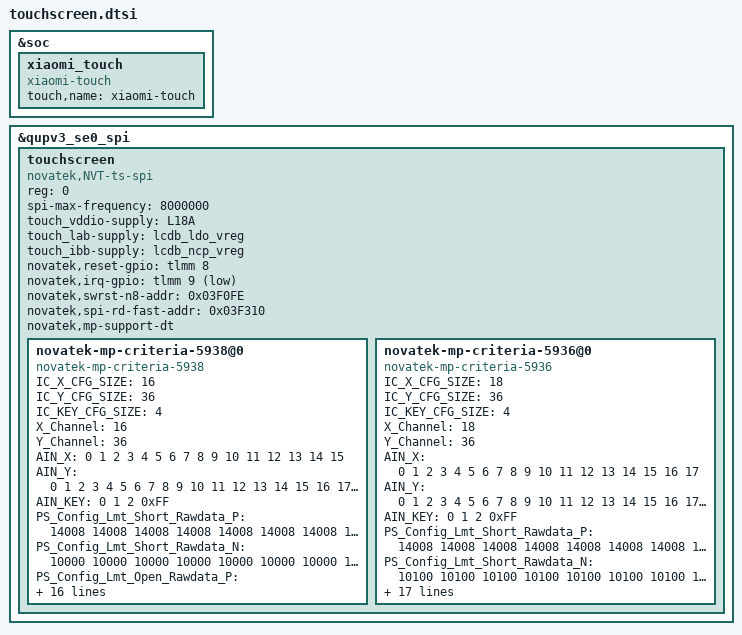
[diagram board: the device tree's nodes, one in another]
/*
 * TouchScreen Device Tree For Xiaomi J20
 */

&soc {
	xiaomi_touch {
		status = "ok";
		compatible = "xiaomi-touch";
		touch,name = "xiaomi-touch";
	};
};

&qupv3_se0_spi {
	status = "ok";

	touchscreen {
		status = "ok";
		compatible = "novatek,NVT-ts-spi";
		reg = <0 >;	//Same as CS ID

		/* SPI Configuration */
		spi-max-frequency = <8000000 >;	//4800000,5000000,8000000,9600000,15000000,19200000

		/* regulator Configuration */
		touch_vddio-supply = <&L18A>;
		touch_lab-supply = <&lcdb_ldo_vreg>;
		touch_ibb-supply = <&lcdb_ncp_vreg>;

		/*Novatek GPIO Configuration */
		novatek,reset-gpio = <&tlmm 8 0x00>;
		novatek,irq-gpio = <&tlmm 9 0x2001>;

		/* 525 */
		//novatek,swrst-n8-addr = <0x01F01A>;

		/* 672A, 525B, 675, 526 */
		novatek,swrst-n8-addr = <0x03F0FE>;
		novatek,spi-rd-fast-addr = <0x03F310>;

		/* MP */
		novatek,mp-support-dt;

		/*for Xiaomi J20 672C TM6.67" module*/
		novatek-mp-criteria-5938@0 {
			#address-cells = <1>;
			#size-cells = <0>;
			compatible = "novatek-mp-criteria-5938";

			/* MP Config */
			IC_X_CFG_SIZE = <16>;
			IC_Y_CFG_SIZE = <36>;
			IC_KEY_CFG_SIZE = <4>;
			X_Channel = <16>;
			Y_Channel = <36>;
			AIN_X = <0 1 2 3 4 5 6 7 8 9 10 11 12 13 14 15>;
			AIN_Y = <0 1 2 3 4 5 6 7 8 9 10 11 12 13 14 15 16 17
						18 19 20 21 22 23 24 25 26 27 28 29 30 31 32 33 34 35>;
			AIN_KEY = <0 1 2 0xFF>;

			/* MP Criteria */
			PS_Config_Lmt_Short_Rawdata_P = <
				14008 14008 14008 14008 14008 14008 14008 14008 14008 14008 14008 14008 14008 14008 14008 14008
				14008 14008 14008 14008 14008 14008 14008 14008 14008 14008 14008 14008 14008 14008 14008 14008
				14008 14008 14008 14008 14008 14008 14008 14008 14008 14008 14008 14008 14008 14008 14008 14008
				14008 14008 14008 14008 14008 14008 14008 14008 14008 14008 14008 14008 14008 14008 14008 14008
				14008 14008 14008 14008 14008 14008 14008 14008 14008 14008 14008 14008 14008 14008 14008 14008
				14008 14008 14008 14008 14008 14008 14008 14008 14008 14008 14008 14008 14008 14008 14008 14008
				14008 14008 14008 14008 14008 14008 14008 14008 14008 14008 14008 14008 14008 14008 14008 14008
				14008 14008 14008 14008 14008 14008 14008 14008 14008 14008 14008 14008 14008 14008 14008 14008
				14008 14008 14008 14008 14008 14008 14008 14008 14008 14008 14008 14008 14008 14008 14008 14008
				14008 14008 14008 14008 14008 14008 14008 14008 14008 14008 14008 14008 14008 14008 14008 14008
				14008 14008 14008 14008 14008 14008 14008 14008 14008 14008 14008 14008 14008 14008 14008 14008
				14008 14008 14008 14008 14008 14008 14008 14008 14008 14008 14008 14008 14008 14008 14008 14008
				14008 14008 14008 14008 14008 14008 14008 14008 14008 14008 14008 14008 14008 14008 14008 14008
				14008 14008 14008 14008 14008 14008 14008 14008 14008 14008 14008 14008 14008 14008 14008 14008
				14008 14008 14008 14008 14008 14008 14008 14008 14008 14008 14008 14008 14008 14008 14008 14008
				14008 14008 14008 14008 14008 14008 14008 14008 14008 14008 14008 14008 14008 14008 14008 14008
				14008 14008 14008 14008 14008 14008 14008 14008 14008 14008 14008 14008 14008 14008 14008 14008
				14008 14008 14008 14008 14008 14008 14008 14008 14008 14008 14008 14008 14008 14008 14008 14008
				14008 14008 14008 14008 14008 14008 14008 14008 14008 14008 14008 14008 14008 14008 14008 14008
				14008 14008 14008 14008 14008 14008 14008 14008 14008 14008 14008 14008 14008 14008 14008 14008
				14008 14008 14008 14008 14008 14008 14008 14008 14008 14008 14008 14008 14008 14008 14008 14008
				14008 14008 14008 14008 14008 14008 14008 14008 14008 14008 14008 14008 14008 14008 14008 14008
				14008 14008 14008 14008 14008 14008 14008 14008 14008 14008 14008 14008 14008 14008 14008 14008
				14008 14008 14008 14008 14008 14008 14008 14008 14008 14008 14008 14008 14008 14008 14008 14008
				14008 14008 14008 14008 14008 14008 14008 14008 14008 14008 14008 14008 14008 14008 14008 14008
				14008 14008 14008 14008 14008 14008 14008 14008 14008 14008 14008 14008 14008 14008 14008 14008
				14008 14008 14008 14008 14008 14008 14008 14008 14008 14008 14008 14008 14008 14008 14008 14008
				14008 14008 14008 14008 14008 14008 14008 14008 14008 14008 14008 14008 14008 14008 14008 14008
				14008 14008 14008 14008 14008 14008 14008 14008 14008 14008 14008 14008 14008 14008 14008 14008
				14008 14008 14008 14008 14008 14008 14008 14008 14008 14008 14008 14008 14008 14008 14008 14008
				14008 14008 14008 14008 14008 14008 14008 14008 14008 14008 14008 14008 14008 14008 14008 14008
				14008 14008 14008 14008 14008 14008 14008 14008 14008 14008 14008 14008 14008 14008 14008 14008
				14008 14008 14008 14008 14008 14008 14008 14008 14008 14008 14008 14008 14008 14008 14008 14008
				14008 14008 14008 14008 14008 14008 14008 14008 14008 14008 14008 14008 14008 14008 14008 14008
				14008 14008 14008 14008 14008 14008 14008 14008 14008 14008 14008 14008 14008 14008 14008 14008
				14008 14008 14008 14008 14008 14008 14008 14008 14008 14008 14008 14008 14008 14008 14008 14008
				14008 14008 14008>;

			PS_Config_Lmt_Short_Rawdata_N = <
				10000 10000 10000 10000 10000 10000 10000 10000 10000 10000 10000 10000 10000 10000 10000 10000
				10000 10000 10000 10000 10000 10000 10000 10000 10000 10000 10000 10000 10000 10000 10000 10000
				10000 10000 10000 10000 10000 10000 10000 10000 10000 10000 10000 10000 10000 10000 10000 10000
				10000 10000 10000 10000 10000 10000 10000 10000 10000 10000 10000 10000 10000 10000 10000 10000
				10000 10000 10000 10000 10000 10000 10000 10000 10000 10000 10000 10000 10000 10000 10000 10000
				10000 10000 10000 10000 10000 10000 10000 10000 10000 10000 10000 10000 10000 10000 10000 10000
				10000 10000 10000 10000 10000 10000 10000 10000 10000 10000 10000 10000 10000 10000 10000 10000
				10000 10000 10000 10000 10000 10000 10000 10000 10000 10000 10000 10000 10000 10000 10000 10000
				10000 10000 10000 10000 10000 10000 10000 10000 10000 10000 10000 10000 10000 10000 10000 10000
				10000 10000 10000 10000 10000 10000 10000 10000 10000 10000 10000 10000 10000 10000 10000 10000
				10000 10000 10000 10000 10000 10000 10000 10000 10000 10000 10000 10000 10000 10000 10000 10000
				10000 10000 10000 10000 10000 10000 10000 10000 10000 10000 10000 10000 10000 10000 10000 10000
				10000 10000 10000 10000 10000 10000 10000 10000 10000 10000 10000 10000 10000 10000 10000 10000
				10000 10000 10000 10000 10000 10000 10000 10000 10000 10000 10000 10000 10000 10000 10000 10000
				10000 10000 10000 10000 10000 10000 10000 10000 10000 10000 10000 10000 10000 10000 10000 10000
				10000 10000 10000 10000 10000 10000 10000 10000 10000 10000 10000 10000 10000 10000 10000 10000
				10000 10000 10000 10000 10000 10000 10000 10000 10000 10000 10000 10000 10000 10000 10000 10000
				10000 10000 10000 10000 10000 10000 10000 10000 10000 10000 10000 10000 10000 10000 10000 10000
				10000 10000 10000 10000 10000 10000 10000 10000 10000 10000 10000 10000 10000 10000 10000 10000
				10000 10000 10000 10000 10000 10000 10000 10000 10000 10000 10000 10000 10000 10000 10000 10000
				10000 10000 10000 10000 10000 10000 10000 10000 10000 10000 10000 10000 10000 10000 10000 10000
				10000 10000 10000 10000 10000 10000 10000 10000 10000 10000 10000 10000 10000 10000 10000 10000
				10000 10000 10000 10000 10000 10000 10000 10000 10000 10000 10000 10000 10000 10000 10000 10000
				10000 10000 10000 10000 10000 10000 10000 10000 10000 10000 10000 10000 10000 10000 10000 10000
				10000 10000 10000 10000 10000 10000 10000 10000 10000 10000 10000 10000 10000 10000 10000 10000
				10000 10000 10000 10000 10000 10000 10000 10000 10000 10000 10000 10000 10000 10000 10000 10000
				10000 10000 10000 10000 10000 10000 10000 10000 10000 10000 10000 10000 10000 10000 10000 10000
				10000 10000 10000 10000 10000 10000 10000 10000 10000 10000 10000 10000 10000 10000 10000 10000
				10000 10000 10000 10000 10000 10000 10000 10000 10000 10000 10000 10000 10000 10000 10000 10000
				10000 10000 10000 10000 10000 10000 10000 10000 10000 10000 10000 10000 10000 10000 10000 10000
				10000 10000 10000 10000 10000 10000 10000 10000 10000 10000 10000 10000 10000 10000 10000 10000
				10000 10000 10000 10000 10000 10000 10000 10000 10000 10000 10000 10000 10000 10000 10000 10000
				10000 10000 10000 10000 10000 10000 10000 10000 10000 10000 10000 10000 10000 10000 10000 10000
				10000 10000 10000 10000 10000 10000 10000 10000 10000 10000 10000 10000 10000 10000 10000 10000
				10000 10000 10000 10000 10000 10000 10000 10000 10000 10000 10000 10000 10000 10000 10000 10000
				10000 10000 10000 10000 10000 10000 10000 10000 10000 10000 10000 10000 10000 10000 10000 10000
				10000 10000 10000>;

			PS_Config_Lmt_Open_Rawdata_P = <
				5120 5120 5120 5120 5120 5120 5120 5120 5120 5120 5120 5120 5120 5120 5120 5120
				5120 5120 5120 5120 5120 5120 5120 5120 5120 5120 5120 5120 5120 5120 5120 5120
				5120 5120 5120 5120 5120 5120 5120 5120 5120 5120 5120 5120 5120 5120 5120 5120
				5120 5120 5120 5120 5120 5120 5120 5120 5120 5120 5120 5120 5120 5120 5120 5120
				5120 5120 5120 5120 5120 5120 5120 5120 5120 5120 5120 5120 5120 5120 5120 5120
				5120 5120 5120 5120 5120 5120 5120 5120 5120 5120 5120 5120 5120 5120 5120 5120
				5120 5120 5120 5120 5120 5120 5120 5120 5120 5120 5120 5120 5120 5120 5120 5120
				5120 5120 5120 5120 5120 5120 5120 5120 5120 5120 5120 5120 5120 5120 5120 5120
				5120 5120 5120 5120 5120 5120 5120 5120 5120 5120 5120 5120 5120 5120 5120 5120
				5120 5120 5120 5120 5120 5120 5120 5120 5120 5120 5120 5120 5120 5120 5120 5120
				5120 5120 5120 5120 5120 5120 5120 5120 5120 5120 5120 5120 5120 5120 5120 5120
				5120 5120 5120 5120 5120 5120 5120 5120 5120 5120 5120 5120 5120 5120 5120 5120
				5120 5120 5120 5120 5120 5120 5120 5120 5120 5120 5120 5120 5120 5120 5120 5120
				5120 5120 5120 5120 5120 5120 5120 5120 5120 5120 5120 5120 5120 5120 5120 5120
				5120 5120 5120 5120 5120 5120 5120 5120 5120 5120 5120 5120 5120 5120 5120 5120
				5120 5120 5120 5120 5120 5120 5120 5120 5120 5120 5120 5120 5120 5120 5120 5120
				5120 5120 5120 5120 5120 5120 5120 5120 5120 5120 5120 5120 5120 5120 5120 5120
				5120 5120 5120 5120 5120 5120 5120 5120 5120 5120 5120 5120 5120 5120 5120 5120
				5120 5120 5120 5120 5120 5120 5120 5120 5120 5120 5120 5120 5120 5120 5120 5120
				5120 5120 5120 5120 5120 5120 5120 5120 5120 5120 5120 5120 5120 5120 5120 5120
				5120 5120 5120 5120 5120 5120 5120 5120 5120 5120 5120 5120 5120 5120 5120 5120
				5120 5120 5120 5120 5120 5120 5120 5120 5120 5120 5120 5120 5120 5120 5120 5120
				5120 5120 5120 5120 5120 5120 5120 5120 5120 5120 5120 5120 5120 5120 5120 5120
				5120 5120 5120 5120 5120 5120 5120 5120 5120 5120 5120 5120 5120 5120 5120 5120
				5120 5120 5120 5120 5120 5120 5120 5120 5120 5120 5120 5120 5120 5120 5120 5120
				5120 5120 5120 5120 5120 5120 5120 5120 5120 5120 5120 5120 5120 5120 5120 5120
				5120 5120 5120 5120 5120 5120 5120 5120 5120 5120 5120 5120 5120 5120 5120 5120
				5120 5120 5120 5120 5120 5120 5120 5120 5120 5120 5120 5120 5120 5120 5120 5120
				5120 5120 5120 5120 5120 5120 5120 5120 5120 5120 5120 5120 5120 5120 5120 5120
				5120 5120 5120 5120 5120 5120 5120 5120 5120 5120 5120 5120 5120 5120 5120 5120
				5120 5120 5120 5120 5120 5120 5120 5120 5120 5120 5120 5120 5120 5120 5120 5120
				5120 5120 5120 5120 5120 5120 5120 5120 5120 5120 5120 5120 5120 5120 5120 5120
				5120 5120 5120 5120 5120 5120 5120 5120 5120 5120 5120 5120 5120 5120 5120 5120
				5120 5120 5120 5120 5120 5120 5120 5120 5120 5120 5120 5120 5120 5120 5120 5120
				5120 5120 5120 5120 5120 5120 5120 5120 5120 5120 5120 5120 5120 5120 5120 5120
				5120 5120 5120 5120 5120 5120 5120 5120 5120 5120 5120 5120 5120 5120 5120 5120
				5120 5120 5120>;

			PS_Config_Lmt_Open_Rawdata_N = <
		(-511) (-511) (-511) (-511) (-511) (-511) (-511) (-511) (-511) (-511) (-511) (-511) (-511) (-511) (-511) (-511)
		(-511) (-511) (-511) (-511) (-511) (-511) (-511) (-511) (-511) (-511) (-511) (-511) (-511) (-511) (-511) (-511)
		(-511) (-511) (-511) (-511) (-511) (-511) (-511) (-511) (-511) (-511) (-511) (-511) (-511) (-511) (-511) (-511)
		(-511) (-511) (-511) (-511) (-511) (-511) (-511) (-511) (-511) (-511) (-511) (-511) (-511) (-511) (-511) (-511)
		(-511) (-511) (-511) (-511) (-511) (-511) (-511) (-511) (-511) (-511) (-511) (-511) (-511) (-511) (-511) (-511)
		(-511) (-511) (-511) (-511) (-511) (-511) (-511) (-511) (-511) (-511) (-511) (-511) (-511) (-511) (-511) (-511)
		(-511) (-511) (-511) (-511) (-511) (-511) (-511) (-511) (-511) (-511) (-511) (-511) (-511) (-511) (-511) (-511)
		(-511) (-511) (-511) (-511) (-511) (-511) (-511) (-511) (-511) (-511) (-511) (-511) (-511) (-511) (-511) (-511)
		(-511) (-511) (-511) (-511) (-511) (-511) (-511) (-511) (-511) (-511) (-511) (-511) (-511) (-511) (-511) (-511)
		(-511) (-511) (-511) (-511) (-511) (-511) (-511) (-511) (-511) (-511) (-511) (-511) (-511) (-511) (-511) (-511)
		(-511) (-511) (-511) (-511) (-511) (-511) (-511) (-511) (-511) (-511) (-511) (-511) (-511) (-511) (-511) (-511)
		(-511) (-511) (-511) (-511) (-511) (-511) (-511) (-511) (-511) (-511) (-511) (-511) (-511) (-511) (-511) (-511)
		(-511) (-511) (-511) (-511) (-511) (-511) (-511) (-511) (-511) (-511) (-511) (-511) (-511) (-511) (-511) (-511)
		(-511) (-511) (-511) (-511) (-511) (-511) (-511) (-511) (-511) (-511) (-511) (-511) (-511) (-511) (-511) (-511)
		(-511) (-511) (-511) (-511) (-511) (-511) (-511) (-511) (-511) (-511) (-511) (-511) (-511) (-511) (-511) (-511)
		(-511) (-511) (-511) (-511) (-511) (-511) (-511) (-511) (-511) (-511) (-511) (-511) (-511) (-511) (-511) (-511)
		(-511) (-511) (-511) (-511) (-511) (-511) (-511) (-511) (-511) (-511) (-511) (-511) (-511) (-511) (-511) (-511)
		(-511) (-511) (-511) (-511) (-511) (-511) (-511) (-511) (-511) (-511) (-511) (-511) (-511) (-511) (-511) (-511)
		(-511) (-511) (-511) (-511) (-511) (-511) (-511) (-511) (-511) (-511) (-511) (-511) (-511) (-511) (-511) (-511)
		(-511) (-511) (-511) (-511) (-511) (-511) (-511) (-511) (-511) (-511) (-511) (-511) (-511) (-511) (-511) (-511)
		(-511) (-511) (-511) (-511) (-511) (-511) (-511) (-511) (-511) (-511) (-511) (-511) (-511) (-511) (-511) (-511)
		(-511) (-511) (-511) (-511) (-511) (-511) (-511) (-511) (-511) (-511) (-511) (-511) (-511) (-511) (-511) (-511)
		(-511) (-511) (-511) (-511) (-511) (-511) (-511) (-511) (-511) (-511) (-511) (-511) (-511) (-511) (-511) (-511)
		(-511) (-511) (-511) (-511) (-511) (-511) (-511) (-511) (-511) (-511) (-511) (-511) (-511) (-511) (-511) (-511)
		(-511) (-511) (-511) (-511) (-511) (-511) (-511) (-511) (-511) (-511) (-511) (-511) (-511) (-511) (-511) (-511)
		(-511) (-511) (-511) (-511) (-511) (-511) (-511) (-511) (-511) (-511) (-511) (-511) (-511) (-511) (-511) (-511)
		(-511) (-511) (-511) (-511) (-511) (-511) (-511) (-511) (-511) (-511) (-511) (-511) (-511) (-511) (-511) (-511)
		(-511) (-511) (-511) (-511) (-511) (-511) (-511) (-511) (-511) (-511) (-511) (-511) (-511) (-511) (-511) (-511)
		(-511) (-511) (-511) (-511) (-511) (-511) (-511) (-511) (-511) (-511) (-511) (-511) (-511) (-511) (-511) (-511)
		(-511) (-511) (-511) (-511) (-511) (-511) (-511) (-511) (-511) (-511) (-511) (-511) (-511) (-511) (-511) (-511)
		(-511) (-511) (-511) (-511) (-511) (-511) (-511) (-511) (-511) (-511) (-511) (-511) (-511) (-511) (-511) (-511)
		(-511) (-511) (-511) (-511) (-511) (-511) (-511) (-511) (-511) (-511) (-511) (-511) (-511) (-511) (-511) (-511)
		(-511) (-511) (-511) (-511) (-511) (-511) (-511) (-511) (-511) (-511) (-511) (-511) (-511) (-511) (-511) (-511)
		(-511) (-511) (-511) (-511) (-511) (-511) (-511) (-511) (-511) (-511) (-511) (-511) (-511) (-511) (-511) (-511)
		(-511) (-511) (-511) (-511) (-511) (-511) (-511) (-511) (-511) (-511) (-511) (-511) (-511) (-511) (-511) (-511)
		(-511) (-511) (-511) (-511) (-511) (-511) (-511) (-511) (-511) (-511) (-511) (-511) (-511) (-511) (-511) (-511)
		(-511) (-511) (-511)>;

			PS_Config_Lmt_FW_Rawdata_P = <
				2560 2560 2560 2560 2560 2560 2560 2560 2560 2560 2560 2560 2560 2560 2560 2560
				2560 2560 2560 2560 2560 2560 2560 2560 2560 2560 2560 2560 2560 2560 2560 2560
				2560 2560 2560 2560 2560 2560 2560 2560 2560 2560 2560 2560 2560 2560 2560 2560
				2560 2560 2560 2560 2560 2560 2560 2560 2560 2560 2560 2560 2560 2560 2560 2560
				2560 2560 2560 2560 2560 2560 2560 2560 2560 2560 2560 2560 2560 2560 2560 2560
				2560 2560 2560 2560 2560 2560 2560 2560 2560 2560 2560 2560 2560 2560 2560 2560
				2560 2560 2560 2560 2560 2560 2560 2560 2560 2560 2560 2560 2560 2560 2560 2560
				2560 2560 2560 2560 2560 2560 2560 2560 2560 2560 2560 2560 2560 2560 2560 2560
				2560 2560 2560 2560 2560 2560 2560 2560 2560 2560 2560 2560 2560 2560 2560 2560
				2560 2560 2560 2560 2560 2560 2560 2560 2560 2560 2560 2560 2560 2560 2560 2560
				2560 2560 2560 2560 2560 2560 2560 2560 2560 2560 2560 2560 2560 2560 2560 2560
				2560 2560 2560 2560 2560 2560 2560 2560 2560 2560 2560 2560 2560 2560 2560 2560
				2560 2560 2560 2560 2560 2560 2560 2560 2560 2560 2560 2560 2560 2560 2560 2560
				2560 2560 2560 2560 2560 2560 2560 2560 2560 2560 2560 2560 2560 2560 2560 2560
				2560 2560 2560 2560 2560 2560 2560 2560 2560 2560 2560 2560 2560 2560 2560 2560
				2560 2560 2560 2560 2560 2560 2560 2560 2560 2560 2560 2560 2560 2560 2560 2560
				2560 2560 2560 2560 2560 2560 2560 2560 2560 2560 2560 2560 2560 2560 2560 2560
				2560 2560 2560 2560 2560 2560 2560 2560 2560 2560 2560 2560 2560 2560 2560 2560
				2560 2560 2560 2560 2560 2560 2560 2560 2560 2560 2560 2560 2560 2560 2560 2560
				2560 2560 2560 2560 2560 2560 2560 2560 2560 2560 2560 2560 2560 2560 2560 2560
				2560 2560 2560 2560 2560 2560 2560 2560 2560 2560 2560 2560 2560 2560 2560 2560
				2560 2560 2560 2560 2560 2560 2560 2560 2560 2560 2560 2560 2560 2560 2560 2560
				2560 2560 2560 2560 2560 2560 2560 2560 2560 2560 2560 2560 2560 2560 2560 2560
				2560 2560 2560 2560 2560 2560 2560 2560 2560 2560 2560 2560 2560 2560 2560 2560
				2560 2560 2560 2560 2560 2560 2560 2560 2560 2560 2560 2560 2560 2560 2560 2560
				2560 2560 2560 2560 2560 2560 2560 2560 2560 2560 2560 2560 2560 2560 2560 2560
				2560 2560 2560 2560 2560 2560 2560 2560 2560 2560 2560 2560 2560 2560 2560 2560
				2560 2560 2560 2560 2560 2560 2560 2560 2560 2560 2560 2560 2560 2560 2560 2560
				2560 2560 2560 2560 2560 2560 2560 2560 2560 2560 2560 2560 2560 2560 2560 2560
				2560 2560 2560 2560 2560 2560 2560 2560 2560 2560 2560 2560 2560 2560 2560 2560
				2560 2560 2560 2560 2560 2560 2560 2560 2560 2560 2560 2560 2560 2560 2560 2560
				2560 2560 2560 2560 2560 2560 2560 2560 2560 2560 2560 2560 2560 2560 2560 2560
				2560 2560 2560 2560 2560 2560 2560 2560 2560 2560 2560 2560 2560 2560 2560 2560
				2560 2560 2560 2560 2560 2560 2560 2560 2560 2560 2560 2560 2560 2560 2560 2560
				2560 2560 2560 2560 2560 2560 2560 2560 2560 2560 2560 2560 2560 2560 2560 2560
				2560 2560 2560 2560 2560 2560 2560 2560 2560 2560 2560 2560 2560 2560 2560 2560
				2560 2560 2560>;

			PS_Config_Lmt_FW_Rawdata_N = <
				240 240 240 240 240 240 240 240 240 240 240 240 240 240 240 240
				240 240 240 240 240 240 240 240 240 240 240 240 240 240 240 240
				240 240 240 240 240 240 240 240 240 240 240 240 240 240 240 240
				240 240 240 240 240 240 240 240 240 240 240 240 240 240 240 240
				240 240 240 240 240 240 240 240 240 240 240 240 240 240 240 240
				240 240 240 240 240 240 240 240 240 240 240 240 240 240 240 240
				240 240 240 240 240 240 240 240 240 240 240 240 240 240 240 240
				240 240 240 240 240 240 240 240 240 240 240 240 240 240 240 240
				240 240 240 240 240 240 240 240 240 240 240 240 240 240 240 240
				240 240 240 240 240 240 240 240 240 240 240 240 240 240 240 240
				240 240 240 240 240 240 240 240 240 240 240 240 240 240 240 240
				240 240 240 240 240 240 240 240 240 240 240 240 240 240 240 240
				240 240 240 240 240 240 240 240 240 240 240 240 240 240 240 240
				240 240 240 240 240 240 240 240 240 240 240 240 240 240 240 240
				240 240 240 240 240 240 240 240 240 240 240 240 240 240 240 240
				240 240 240 240 240 240 240 240 240 240 240 240 240 240 240 240
				240 240 240 240 240 240 240 240 240 240 240 240 240 240 240 240
				240 240 240 240 240 240 240 240 240 240 240 240 240 240 240 240
				240 240 240 240 240 240 240 240 240 240 240 240 240 240 240 240
				240 240 240 240 240 240 240 240 240 240 240 240 240 240 240 240
				240 240 240 240 240 240 240 240 240 240 240 240 240 240 240 240
				240 240 240 240 240 240 240 240 240 240 240 240 240 240 240 240
				240 240 240 240 240 240 240 240 240 240 240 240 240 240 240 240
				240 240 240 240 240 240 240 240 240 240 240 240 240 240 240 240
				240 240 240 240 240 240 240 240 240 240 240 240 240 240 240 240
				240 240 240 240 240 240 240 240 240 240 240 240 240 240 240 240
				240 240 240 240 240 240 240 240 240 240 240 240 240 240 240 240
				240 240 240 240 240 240 240 240 240 240 240 240 240 240 240 240
				240 240 240 240 240 240 240 240 240 240 240 240 240 240 240 240
				240 240 240 240 240 240 240 240 240 240 240 240 240 240 240 240
				240 240 240 240 240 240 240 240 240 240 240 240 240 240 240 240
				240 240 240 240 240 240 240 240 240 240 240 240 240 240 240 240
				240 240 240 240 240 240 240 240 240 240 240 240 240 240 240 240
				240 240 240 240 240 240 240 240 240 240 240 240 240 240 240 240
				240 240 240 240 240 240 240 240 240 240 240 240 240 240 240 240
				240 240 240 240 240 240 240 240 240 240 240 240 240 240 240 240
				240 240 240>;

			PS_Config_Lmt_FW_CC_P = <
				314 314 314 314 314 314 314 314 314 314 314 314 314 314 314 314
				314 314 314 314 314 314 314 314 314 314 314 314 314 314 314 314
				314 314 314 314 314 314 314 314 314 314 314 314 314 314 314 314
				314 314 314 314 314 314 314 314 314 314 314 314 314 314 314 314
				314 314 314 314 314 314 314 314 314 314 314 314 314 314 314 314
				314 314 314 314 314 314 314 314 314 314 314 314 314 314 314 314
				314 314 314 314 314 314 314 314 314 314 314 314 314 314 314 314
				314 314 314 314 314 314 314 314 314 314 314 314 314 314 314 314
				314 314 314 314 314 314 314 314 314 314 314 314 314 314 314 314
				314 314 314 314 314 314 314 314 314 314 314 314 314 314 314 314
				314 314 314 314 314 314 314 314 314 314 314 314 314 314 314 314
				314 314 314 314 314 314 314 314 314 314 314 314 314 314 314 314
				314 314 314 314 314 314 314 314 314 314 314 314 314 314 314 314
				314 314 314 314 314 314 314 314 314 314 314 314 314 314 314 314
				314 314 314 314 314 314 314 314 314 314 314 314 314 314 314 314
				314 314 314 314 314 314 314 314 314 314 314 314 314 314 314 314
				314 314 314 314 314 314 314 314 314 314 314 314 314 314 314 314
				314 314 314 314 314 314 314 314 314 314 314 314 314 314 314 314
				314 314 314 314 314 314 314 314 314 314 314 314 314 314 314 314
				314 314 314 314 314 314 314 314 314 314 314 314 314 314 314 314
				314 314 314 314 314 314 314 314 314 314 314 314 314 314 314 314
				314 314 314 314 314 314 314 314 314 314 314 314 314 314 314 314
				314 314 314 314 314 314 314 314 314 314 314 314 314 314 314 314
				314 314 314 314 314 314 314 314 314 314 314 314 314 314 314 314
				314 314 314 314 314 314 314 314 314 314 314 314 314 314 314 314
				314 314 314 314 314 314 314 314 314 314 314 314 314 314 314 314
				314 314 314 314 314 314 314 314 314 314 314 314 314 314 314 314
				314 314 314 314 314 314 314 314 314 314 314 314 314 314 314 314
				314 314 314 314 314 314 314 314 314 314 314 314 314 314 314 314
				314 314 314 314 314 314 314 314 314 314 314 314 314 314 314 314
				314 314 314 314 314 314 314 314 314 314 314 314 314 314 314 314
				314 314 314 314 314 314 314 314 314 314 314 314 314 314 314 314
				314 314 314 314 314 314 314 314 314 314 314 314 314 314 314 314
				314 314 314 314 314 314 314 314 314 314 314 314 314 314 314 314
				314 314 314 314 314 314 314 314 314 314 314 314 314 314 314 314
				314 314 314 314 314 314 314 314 314 314 314 314 314 314 314 314
				314 314 314>;

			PS_Config_Lmt_FW_CC_N = <
				0 0 0 0 0 0 0 0 0 0 0 0 0 0 0 0
				0 0 0 0 0 0 0 0 0 0 0 0 0 0 0 0
				0 0 0 0 0 0 0 0 0 0 0 0 0 0 0 0
				0 0 0 0 0 0 0 0 0 0 0 0 0 0 0 0
				0 0 0 0 0 0 0 0 0 0 0 0 0 0 0 0
				0 0 0 0 0 0 0 0 0 0 0 0 0 0 0 0
				0 0 0 0 0 0 0 0 0 0 0 0 0 0 0 0
				0 0 0 0 0 0 0 0 0 0 0 0 0 0 0 0
				0 0 0 0 0 0 0 0 0 0 0 0 0 0 0 0
				0 0 0 0 0 0 0 0 0 0 0 0 0 0 0 0
				0 0 0 0 0 0 0 0 0 0 0 0 0 0 0 0
				0 0 0 0 0 0 0 0 0 0 0 0 0 0 0 0
				0 0 0 0 0 0 0 0 0 0 0 0 0 0 0 0
				0 0 0 0 0 0 0 0 0 0 0 0 0 0 0 0
				0 0 0 0 0 0 0 0 0 0 0 0 0 0 0 0
				0 0 0 0 0 0 0 0 0 0 0 0 0 0 0 0
				0 0 0 0 0 0 0 0 0 0 0 0 0 0 0 0
				0 0 0 0 0 0 0 0 0 0 0 0 0 0 0 0
				0 0 0 0 0 0 0 0 0 0 0 0 0 0 0 0
				0 0 0 0 0 0 0 0 0 0 0 0 0 0 0 0
				0 0 0 0 0 0 0 0 0 0 0 0 0 0 0 0
				0 0 0 0 0 0 0 0 0 0 0 0 0 0 0 0
				0 0 0 0 0 0 0 0 0 0 0 0 0 0 0 0
				0 0 0 0 0 0 0 0 0 0 0 0 0 0 0 0
				0 0 0 0 0 0 0 0 0 0 0 0 0 0 0 0
				0 0 0 0 0 0 0 0 0 0 0 0 0 0 0 0
				0 0 0 0 0 0 0 0 0 0 0 0 0 0 0 0
				0 0 0 0 0 0 0 0 0 0 0 0 0 0 0 0
				0 0 0 0 0 0 0 0 0 0 0 0 0 0 0 0
				0 0 0 0 0 0 0 0 0 0 0 0 0 0 0 0
				0 0 0 0 0 0 0 0 0 0 0 0 0 0 0 0
				0 0 0 0 0 0 0 0 0 0 0 0 0 0 0 0
				0 0 0 0 0 0 0 0 0 0 0 0 0 0 0 0
				0 0 0 0 0 0 0 0 0 0 0 0 0 0 0 0
				0 0 0 0 0 0 0 0 0 0 0 0 0 0 0 0
				0 0 0 0 0 0 0 0 0 0 0 0 0 0 0 0
				0 0 0>;

			PS_Config_Lmt_FW_Diff_P = <
				75 75 75 75 75 75 75 75 75 75 75 75 75 75 75 75
				75 75 75 75 75 75 75 75 75 75 75 75 75 75 75 75
				75 75 75 75 75 75 75 75 75 75 75 75 75 75 75 75
				75 75 75 75 75 75 75 75 75 75 75 75 75 75 75 75
				75 75 75 75 75 75 75 75 75 75 75 75 75 75 75 75
				75 75 75 75 75 75 75 75 75 75 75 75 75 75 75 75
				75 75 75 75 75 75 75 75 75 75 75 75 75 75 75 75
				75 75 75 75 75 75 75 75 75 75 75 75 75 75 75 75
				75 75 75 75 75 75 75 75 75 75 75 75 75 75 75 75
				75 75 75 75 75 75 75 75 75 75 75 75 75 75 75 75
				75 75 75 75 75 75 75 75 75 75 75 75 75 75 75 75
				75 75 75 75 75 75 75 75 75 75 75 75 75 75 75 75
				75 75 75 75 75 75 75 75 75 75 75 75 75 75 75 75
				75 75 75 75 75 75 75 75 75 75 75 75 75 75 75 75
				75 75 75 75 75 75 75 75 75 75 75 75 75 75 75 75
				75 75 75 75 75 75 75 75 75 75 75 75 75 75 75 75
				75 75 75 75 75 75 75 75 75 75 75 75 75 75 75 75
				75 75 75 75 75 75 75 75 75 75 75 75 75 75 75 75
				75 75 75 75 75 75 75 75 75 75 75 75 75 75 75 75
				75 75 75 75 75 75 75 75 75 75 75 75 75 75 75 75
				75 75 75 75 75 75 75 75 75 75 75 75 75 75 75 75
				75 75 75 75 75 75 75 75 75 75 75 75 75 75 75 75
				75 75 75 75 75 75 75 75 75 75 75 75 75 75 75 75
				75 75 75 75 75 75 75 75 75 75 75 75 75 75 75 75
				75 75 75 75 75 75 75 75 75 75 75 75 75 75 75 75
				75 75 75 75 75 75 75 75 75 75 75 75 75 75 75 75
				75 75 75 75 75 75 75 75 75 75 75 75 75 75 75 75
				75 75 75 75 75 75 75 75 75 75 75 75 75 75 75 75
				75 75 75 75 75 75 75 75 75 75 75 75 75 75 75 75
				75 75 75 75 75 75 75 75 75 75 75 75 75 75 75 75
				75 75 75 75 75 75 75 75 75 75 75 75 75 75 75 75
				75 75 75 75 75 75 75 75 75 75 75 75 75 75 75 75
				75 75 75 75 75 75 75 75 75 75 75 75 75 75 75 75
				75 75 75 75 75 75 75 75 75 75 75 75 75 75 75 75
				75 75 75 75 75 75 75 75 75 75 75 75 75 75 75 75
				75 75 75 75 75 75 75 75 75 75 75 75 75 75 75 75
				75 75 75>;

			PS_Config_Lmt_FW_Diff_N = <
				(-75) (-75) (-75) (-75) (-75) (-75) (-75) (-75) (-75) (-75) (-75) (-75) (-75) (-75) (-75) (-75)
				(-75) (-75) (-75) (-75) (-75) (-75) (-75) (-75) (-75) (-75) (-75) (-75) (-75) (-75) (-75) (-75)
				(-75) (-75) (-75) (-75) (-75) (-75) (-75) (-75) (-75) (-75) (-75) (-75) (-75) (-75) (-75) (-75)
				(-75) (-75) (-75) (-75) (-75) (-75) (-75) (-75) (-75) (-75) (-75) (-75) (-75) (-75) (-75) (-75)
				(-75) (-75) (-75) (-75) (-75) (-75) (-75) (-75) (-75) (-75) (-75) (-75) (-75) (-75) (-75) (-75)
				(-75) (-75) (-75) (-75) (-75) (-75) (-75) (-75) (-75) (-75) (-75) (-75) (-75) (-75) (-75) (-75)
				(-75) (-75) (-75) (-75) (-75) (-75) (-75) (-75) (-75) (-75) (-75) (-75) (-75) (-75) (-75) (-75)
				(-75) (-75) (-75) (-75) (-75) (-75) (-75) (-75) (-75) (-75) (-75) (-75) (-75) (-75) (-75) (-75)
				(-75) (-75) (-75) (-75) (-75) (-75) (-75) (-75) (-75) (-75) (-75) (-75) (-75) (-75) (-75) (-75)
				(-75) (-75) (-75) (-75) (-75) (-75) (-75) (-75) (-75) (-75) (-75) (-75) (-75) (-75) (-75) (-75)
				(-75) (-75) (-75) (-75) (-75) (-75) (-75) (-75) (-75) (-75) (-75) (-75) (-75) (-75) (-75) (-75)
				(-75) (-75) (-75) (-75) (-75) (-75) (-75) (-75) (-75) (-75) (-75) (-75) (-75) (-75) (-75) (-75)
				(-75) (-75) (-75) (-75) (-75) (-75) (-75) (-75) (-75) (-75) (-75) (-75) (-75) (-75) (-75) (-75)
				(-75) (-75) (-75) (-75) (-75) (-75) (-75) (-75) (-75) (-75) (-75) (-75) (-75) (-75) (-75) (-75)
				(-75) (-75) (-75) (-75) (-75) (-75) (-75) (-75) (-75) (-75) (-75) (-75) (-75) (-75) (-75) (-75)
				(-75) (-75) (-75) (-75) (-75) (-75) (-75) (-75) (-75) (-75) (-75) (-75) (-75) (-75) (-75) (-75)
				(-75) (-75) (-75) (-75) (-75) (-75) (-75) (-75) (-75) (-75) (-75) (-75) (-75) (-75) (-75) (-75)
				(-75) (-75) (-75) (-75) (-75) (-75) (-75) (-75) (-75) (-75) (-75) (-75) (-75) (-75) (-75) (-75)
				(-75) (-75) (-75) (-75) (-75) (-75) (-75) (-75) (-75) (-75) (-75) (-75) (-75) (-75) (-75) (-75)
				(-75) (-75) (-75) (-75) (-75) (-75) (-75) (-75) (-75) (-75) (-75) (-75) (-75) (-75) (-75) (-75)
				(-75) (-75) (-75) (-75) (-75) (-75) (-75) (-75) (-75) (-75) (-75) (-75) (-75) (-75) (-75) (-75)
				(-75) (-75) (-75) (-75) (-75) (-75) (-75) (-75) (-75) (-75) (-75) (-75) (-75) (-75) (-75) (-75)
				(-75) (-75) (-75) (-75) (-75) (-75) (-75) (-75) (-75) (-75) (-75) (-75) (-75) (-75) (-75) (-75)
				(-75) (-75) (-75) (-75) (-75) (-75) (-75) (-75) (-75) (-75) (-75) (-75) (-75) (-75) (-75) (-75)
				(-75) (-75) (-75) (-75) (-75) (-75) (-75) (-75) (-75) (-75) (-75) (-75) (-75) (-75) (-75) (-75)
				(-75) (-75) (-75) (-75) (-75) (-75) (-75) (-75) (-75) (-75) (-75) (-75) (-75) (-75) (-75) (-75)
				(-75) (-75) (-75) (-75) (-75) (-75) (-75) (-75) (-75) (-75) (-75) (-75) (-75) (-75) (-75) (-75)
				(-75) (-75) (-75) (-75) (-75) (-75) (-75) (-75) (-75) (-75) (-75) (-75) (-75) (-75) (-75) (-75)
				(-75) (-75) (-75) (-75) (-75) (-75) (-75) (-75) (-75) (-75) (-75) (-75) (-75) (-75) (-75) (-75)
				(-75) (-75) (-75) (-75) (-75) (-75) (-75) (-75) (-75) (-75) (-75) (-75) (-75) (-75) (-75) (-75)
				(-75) (-75) (-75) (-75) (-75) (-75) (-75) (-75) (-75) (-75) (-75) (-75) (-75) (-75) (-75) (-75)
				(-75) (-75) (-75) (-75) (-75) (-75) (-75) (-75) (-75) (-75) (-75) (-75) (-75) (-75) (-75) (-75)
				(-75) (-75) (-75) (-75) (-75) (-75) (-75) (-75) (-75) (-75) (-75) (-75) (-75) (-75) (-75) (-75)
				(-75) (-75) (-75) (-75) (-75) (-75) (-75) (-75) (-75) (-75) (-75) (-75) (-75) (-75) (-75) (-75)
				(-75) (-75) (-75) (-75) (-75) (-75) (-75) (-75) (-75) (-75) (-75) (-75) (-75) (-75) (-75) (-75)
				(-75) (-75) (-75) (-75) (-75) (-75) (-75) (-75) (-75) (-75) (-75) (-75) (-75) (-75) (-75) (-75)
				(-75) (-75) (-75)>;

			PS_Config_Diff_Test_Frame = <50>;
		};

		/*for Xiaomi J20 672C CSOT6.67" module*/
		novatek-mp-criteria-5936@0 {
			#address-cells = <1>;
			#size-cells = <0>;
			compatible = "novatek-mp-criteria-5936";

			/* MP Config */
			IC_X_CFG_SIZE = <18>;
			IC_Y_CFG_SIZE = <36>;
			IC_KEY_CFG_SIZE = <4>;
			X_Channel = <18>;
			Y_Channel = <36>;
			AIN_X = <0 1 2 3 4 5 6 7 8 9 10 11 12 13 14 15 16 17>;
			AIN_Y = <0 1 2 3 4 5 6 7 8 9 10 11 12 13 14 15 16 17
						18 19 20 21 22 23 24 25 26 27 28 29 30 31 32 33 34 35>;
			AIN_KEY = <0 1 2 0xFF>;

			/* MP Criteria */
			PS_Config_Lmt_Short_Rawdata_P = <
				14008 14008 14008 14008 14008 14008 14008 14008 14008 14008 14008 14008 14008 14008 14008 14008 14008 14008
				14008 14008 14008 14008 14008 14008 14008 14008 14008 14008 14008 14008 14008 14008 14008 14008 14008 14008
				14008 14008 14008 14008 14008 14008 14008 14008 14008 14008 14008 14008 14008 14008 14008 14008 14008 14008
				14008 14008 14008 14008 14008 14008 14008 14008 14008 14008 14008 14008 14008 14008 14008 14008 14008 14008
				14008 14008 14008 14008 14008 14008 14008 14008 14008 14008 14008 14008 14008 14008 14008 14008 14008 14008
				14008 14008 14008 14008 14008 14008 14008 14008 14008 14008 14008 14008 14008 14008 14008 14008 14008 14008
				14008 14008 14008 14008 14008 14008 14008 14008 14008 14008 14008 14008 14008 14008 14008 14008 14008 14008
				14008 14008 14008 14008 14008 14008 14008 14008 14008 14008 14008 14008 14008 14008 14008 14008 14008 14008
				14008 14008 14008 14008 14008 14008 14008 14008 14008 14008 14008 14008 14008 14008 14008 14008 14008 14008
				14008 14008 14008 14008 14008 14008 14008 14008 14008 14008 14008 14008 14008 14008 14008 14008 14008 14008
				14008 14008 14008 14008 14008 14008 14008 14008 14008 14008 14008 14008 14008 14008 14008 14008 14008 14008
				14008 14008 14008 14008 14008 14008 14008 14008 14008 14008 14008 14008 14008 14008 14008 14008 14008 14008
				14008 14008 14008 14008 14008 14008 14008 14008 14008 14008 14008 14008 14008 14008 14008 14008 14008 14008
				14008 14008 14008 14008 14008 14008 14008 14008 14008 14008 14008 14008 14008 14008 14008 14008 14008 14008
				14008 14008 14008 14008 14008 14008 14008 14008 14008 14008 14008 14008 14008 14008 14008 14008 14008 14008
				14008 14008 14008 14008 14008 14008 14008 14008 14008 14008 14008 14008 14008 14008 14008 14008 14008 14008
				14008 14008 14008 14008 14008 14008 14008 14008 14008 14008 14008 14008 14008 14008 14008 14008 14008 14008
				14008 14008 14008 14008 14008 14008 14008 14008 14008 14008 14008 14008 14008 14008 14008 14008 14008 14008
				14008 14008 14008 14008 14008 14008 14008 14008 14008 14008 14008 14008 14008 14008 14008 14008 14008 14008
				14008 14008 14008 14008 14008 14008 14008 14008 14008 14008 14008 14008 14008 14008 14008 14008 14008 14008
				14008 14008 14008 14008 14008 14008 14008 14008 14008 14008 14008 14008 14008 14008 14008 14008 14008 14008
				14008 14008 14008 14008 14008 14008 14008 14008 14008 14008 14008 14008 14008 14008 14008 14008 14008 14008
				14008 14008 14008 14008 14008 14008 14008 14008 14008 14008 14008 14008 14008 14008 14008 14008 14008 14008
				14008 14008 14008 14008 14008 14008 14008 14008 14008 14008 14008 14008 14008 14008 14008 14008 14008 14008
				14008 14008 14008 14008 14008 14008 14008 14008 14008 14008 14008 14008 14008 14008 14008 14008 14008 14008
				14008 14008 14008 14008 14008 14008 14008 14008 14008 14008 14008 14008 14008 14008 14008 14008 14008 14008
				14008 14008 14008 14008 14008 14008 14008 14008 14008 14008 14008 14008 14008 14008 14008 14008 14008 14008
				14008 14008 14008 14008 14008 14008 14008 14008 14008 14008 14008 14008 14008 14008 14008 14008 14008 14008
				14008 14008 14008 14008 14008 14008 14008 14008 14008 14008 14008 14008 14008 14008 14008 14008 14008 14008
				14008 14008 14008 14008 14008 14008 14008 14008 14008 14008 14008 14008 14008 14008 14008 14008 14008 14008
				14008 14008 14008 14008 14008 14008 14008 14008 14008 14008 14008 14008 14008 14008 14008 14008 14008 14008
				14008 14008 14008 14008 14008 14008 14008 14008 14008 14008 14008 14008 14008 14008 14008 14008 14008 14008
				14008 14008 14008 14008 14008 14008 14008 14008 14008 14008 14008 14008 14008 14008 14008 14008 14008 14008
				14008 14008 14008 14008 14008 14008 14008 14008 14008 14008 14008 14008 14008 14008 14008 14008 14008 14008
				14008 14008 14008 14008 14008 14008 14008 14008 14008 14008 14008 14008 14008 14008 14008 14008 14008 14008
				14008 14008 14008 14008 14008 14008 14008 14008 14008 14008 14008 14008 14008 14008 14008 14008 14008 14008
				14008 14008 14008>;

			PS_Config_Lmt_Short_Rawdata_N = <
				10100 10100 10100 10100 10100 10100 10100 10100 10100 10100 10100 10100 10100 10100 10100 10100 10100 10100
				10100 10100 10100 10100 10100 10100 10100 10100 10100 10100 10100 10100 10100 10100 10100 10100 10100 10100
				10100 10100 10100 10100 10100 10100 10100 10100 10100 10100 10100 10100 10100 10100 10100 10100 10100 10100
				10100 10100 10100 10100 10100 10100 10100 10100 10100 10100 10100 10100 10100 10100 10100 10100 10100 10100
				10100 10100 10100 10100 10100 10100 10100 10100 10100 10100 10100 10100 10100 10100 10100 10100 10100 10100
				10100 10100 10100 10100 10100 10100 10100 10100 10100 10100 10100 10100 10100 10100 10100 10100 10100 10100
				10100 10100 10100 10100 10100 10100 10100 10100 10100 10100 10100 10100 10100 10100 10100 10100 10100 10100
				10100 10100 10100 10100 10100 10100 10100 10100 10100 10100 10100 10100 10100 10100 10100 10100 10100 10100
				10100 10100 10100 10100 10100 10100 10100 10100 10100 10100 10100 10100 10100 10100 10100 10100 10100 10100
				10100 10100 10100 10100 10100 10100 10100 10100 10100 10100 10100 10100 10100 10100 10100 10100 10100 10100
				10100 10100 10100 10100 10100 10100 10100 10100 10100 10100 10100 10100 10100 10100 10100 10100 10100 10100
				10100 10100 10100 10100 10100 10100 10100 10100 10100 10100 10100 10100 10100 10100 10100 10100 10100 10100
				10100 10100 10100 10100 10100 10100 10100 10100 10100 10100 10100 10100 10100 10100 10100 10100 10100 10100
				10100 10100 10100 10100 10100 10100 10100 10100 10100 10100 10100 10100 10100 10100 10100 10100 10100 10100
				10100 10100 10100 10100 10100 10100 10100 10100 10100 10100 10100 10100 10100 10100 10100 10100 10100 10100
				10100 10100 10100 10100 10100 10100 10100 10100 10100 10100 10100 10100 10100 10100 10100 10100 10100 10100
				10100 10100 10100 10100 10100 10100 10100 10100 10100 10100 10100 10100 10100 10100 10100 10100 10100 10100
				10100 10100 10100 10100 10100 10100 10100 10100 10100 10100 10100 10100 10100 10100 10100 10100 10100 10100
				10100 10100 10100 10100 10100 10100 10100 10100 10100 10100 10100 10100 10100 10100 10100 10100 10100 10100
				10100 10100 10100 10100 10100 10100 10100 10100 10100 10100 10100 10100 10100 10100 10100 10100 10100 10100
				10100 10100 10100 10100 10100 10100 10100 10100 10100 10100 10100 10100 10100 10100 10100 10100 10100 10100
				10100 10100 10100 10100 10100 10100 10100 10100 10100 10100 10100 10100 10100 10100 10100 10100 10100 10100
				10100 10100 10100 10100 10100 10100 10100 10100 10100 10100 10100 10100 10100 10100 10100 10100 10100 10100
				10100 10100 10100 10100 10100 10100 10100 10100 10100 10100 10100 10100 10100 10100 10100 10100 10100 10100
				10100 10100 10100 10100 10100 10100 10100 10100 10100 10100 10100 10100 10100 10100 10100 10100 10100 10100
				10100 10100 10100 10100 10100 10100 10100 10100 10100 10100 10100 10100 10100 10100 10100 10100 10100 10100
				10100 10100 10100 10100 10100 10100 10100 10100 10100 10100 10100 10100 10100 10100 10100 10100 10100 10100
				10100 10100 10100 10100 10100 10100 10100 10100 10100 10100 10100 10100 10100 10100 10100 10100 10100 10100
				10100 10100 10100 10100 10100 10100 10100 10100 10100 10100 10100 10100 10100 10100 10100 10100 10100 10100
				10100 10100 10100 10100 10100 10100 10100 10100 10100 10100 10100 10100 10100 10100 10100 10100 10100 10100
				10100 10100 10100 10100 10100 10100 10100 10100 10100 10100 10100 10100 10100 10100 10100 10100 10100 10100
				10100 10100 10100 10100 10100 10100 10100 10100 10100 10100 10100 10100 10100 10100 10100 10100 10100 10100
				10100 10100 10100 10100 10100 10100 10100 10100 10100 10100 10100 10100 10100 10100 10100 10100 10100 10100
				10100 10100 10100 10100 10100 10100 10100 10100 10100 10100 10100 10100 10100 10100 10100 10100 10100 10100
				10100 10100 10100 10100 10100 10100 10100 10100 10100 10100 10100 10100 10100 10100 10100 10100 10100 10100
				10100 10100 10100 10100 10100 10100 10100 10100 10100 10100 10100 10100 10100 10100 10100 10100 10100 10100
				10000 10000 10000>;

			PS_Config_Lmt_Open_Rawdata_P = <
				2496 2945 2706 3018 2730 2997 2758 3029 2776 2856 3147 2860 3113 2837 3130 2776 3018 2625
				2686 3053 2753 3084 2776 3099 2815 3138 2886 2923 3185 2878 3158 2861 3159 2819 3094 2704
				2636 3047 2749 3094 2773 3101 2804 3137 2864 2989 3249 2940 3208 2906 3199 2833 3091 2773
				2731 3108 2811 3179 2843 3199 2886 3246 2948 3000 3292 2966 3281 2948 3278 2884 3166 2759
				2676 3091 2788 3124 2804 3127 2829 3159 2885 3056 3330 3010 3302 2989 3287 2912 3175 2850
				2753 3081 2808 3126 2835 3145 2865 3179 2924 3012 3287 2962 3264 2955 3253 2884 3145 2759
				2671 3144 2788 3176 2811 3180 2836 3210 2902 3110 3404 3052 3371 3026 3344 2931 3220 2856
				2763 3119 2791 3130 2840 3164 2870 3201 2927 3029 3312 2955 3273 2963 3267 2886 3161 2752
				2723 3129 2832 3150 2844 3150 2861 3176 2930 3126 3383 3068 3357 3052 3318 2955 3206 2877
				2843 3211 2882 3239 2905 3250 2930 3285 2994 3109 3393 3049 3376 3040 3350 2945 3238 2808
				2752 3155 2856 3176 2847 3155 2886 3199 2949 3115 3381 3063 3353 3024 3290 2935 3192 2844
				2798 3136 2826 3168 2854 3185 2888 3220 2951 3105 3354 3043 3336 3035 3299 2933 3192 2794
				2766 3197 2867 3225 2884 3229 2896 3253 2968 3218 3491 3168 3466 3144 3402 3011 3276 2920
				2850 3169 2871 3197 2895 3210 2923 3238 2982 3141 3389 3085 3381 3084 3329 2969 3222 2825
				2795 3175 2874 3194 2881 3201 2879 3194 2965 3183 3434 3141 3421 3115 3354 2975 3225 2906
				2891 3238 2909 3256 2920 3273 2954 3299 3007 3211 3479 3152 3460 3131 3396 3010 3291 2868
				2802 3176 2856 3183 2857 3187 2882 3206 2949 3239 3466 3196 3455 3169 3378 3043 3280 2956
				2818 3144 2812 3152 2825 3166 2870 3192 2905 3200 3413 3145 3395 3124 3327 3004 3235 2874
				2839 3196 2940 3339 3082 3409 3116 3438 3143 3010 3322 2976 3287 2941 3278 2916 3242 2970
				2905 3220 2941 3313 3081 3388 3117 3424 3148 2976 3256 2949 3227 2921 3224 2900 3185 2923
				2823 3173 2917 3291 3036 3347 3057 3372 3080 2973 3270 2944 3234 2914 3222 2893 3194 2947
				2944 3288 2983 3388 3120 3452 3161 3494 3189 2986 3315 2968 3288 2938 3291 2923 3253 2931
				2814 3178 2910 3285 3026 3344 3056 3367 3080 2975 3266 2955 3235 2924 3222 2902 3201 2942
				2909 3186 2951 3283 3066 3340 3102 3371 3123 2956 3249 2942 3228 2921 3229 2906 3207 2906
				2672 2993 2759 3091 2856 3127 2884 3157 2909 2842 3112 2815 3080 2786 3067 2758 3040 2784
				2732 2998 2770 3089 2867 3133 2898 3161 2923 2821 3066 2800 3047 2780 3046 2766 3024 2759
				2683 2994 2770 3082 2856 3106 2885 3134 2909 2822 3054 2794 3018 2762 3007 2732 2977 2752
				2723 3042 2766 3136 2860 3172 2900 3208 2942 2884 3141 2853 3117 2828 3120 2808 3098 2783
				2702 3025 2795 3113 2868 3126 2896 3150 2928 2885 3105 2847 3074 2812 3068 2784 3042 2794
				2704 2982 2752 3073 2828 3095 2870 3129 2900 2839 3068 2812 3046 2787 3049 2770 3025 2738
				2700 3047 2798 3141 2858 3148 2891 3176 2917 2923 3155 2892 3126 2861 3122 2833 3085 2823
				2727 3005 2773 3096 2837 3113 2872 3141 2907 2885 3110 2858 3096 2836 3096 2823 3066 2774
				2688 3018 2787 3109 2837 3108 2865 3134 2893 2916 3151 2888 3122 2854 3112 2832 3074 2816
				2745 3073 2802 3171 2867 3186 2909 3228 2951 2934 3175 2905 3154 2881 3155 2865 3112 2802
				2473 3024 2781 3103 2826 3106 2854 3131 2885 2905 3133 2875 3102 2840 3096 2818 3046 2564
				2536 3038 2833 3133 2884 3179 2923 3172 2948 2895 3158 2881 3168 2857 3144 2839 3087 2587
				5120 5120 5120>;

			PS_Config_Lmt_Open_Rawdata_N = <
				1069 1262 1159 1293 1170 1284 1182 1298 1189 1224 1348 1225 1334 1216 1341 1189 1293 1125
				1151 1308 1180 1321 1189 1328 1206 1345 1237 1252 1365 1233 1353 1226 1354 1208 1326 1159
				1129 1306 1178 1326 1188 1329 1201 1344 1227 1281 1392 1260 1375 1245 1371 1214 1324 1188
				1170 1332 1204 1362 1218 1371 1237 1391 1263 1285 1411 1271 1406 1263 1405 1236 1357 1182
				1147 1324 1195 1339 1201 1340 1212 1354 1236 1309 1427 1290 1415 1281 1408 1248 1360 1221
				1180 1320 1203 1339 1215 1348 1228 1362 1253 1291 1408 1269 1399 1266 1394 1236 1348 1182
				1144 1347 1195 1361 1204 1363 1215 1375 1243 1333 1459 1308 1444 1297 1433 1256 1380 1224
				1184 1336 1196 1341 1217 1356 1230 1372 1254 1298 1419 1266 1402 1270 1400 1237 1354 1179
				1167 1341 1213 1350 1219 1350 1226 1361 1255 1339 1450 1315 1438 1308 1422 1266 1374 1233
				1218 1376 1235 1388 1245 1393 1255 1408 1283 1332 1454 1306 1447 1303 1435 1262 1387 1203
				1179 1352 1224 1361 1220 1352 1237 1371 1264 1335 1449 1312 1437 1296 1410 1258 1368 1219
				1199 1344 1211 1357 1223 1365 1237 1380 1264 1330 1437 1304 1429 1300 1414 1257 1368 1197
				1185 1370 1228 1382 1236 1384 1241 1394 1272 1379 1496 1357 1485 1347 1458 1290 1404 1251
				1221 1358 1230 1370 1240 1375 1252 1387 1278 1346 1452 1322 1449 1321 1426 1272 1381 1210
				1198 1360 1231 1369 1234 1372 1234 1369 1270 1364 1471 1346 1466 1335 1437 1275 1382 1245
				1239 1387 1246 1395 1251 1402 1266 1414 1288 1376 1491 1351 1483 1342 1455 1290 1410 1229
				1201 1361 1224 1364 1224 1366 1235 1374 1264 1388 1485 1369 1480 1358 1447 1304 1405 1267
				1207 1347 1205 1351 1210 1357 1230 1368 1245 1371 1462 1348 1455 1339 1426 1287 1386 1231
				1216 1369 1260 1431 1321 1461 1335 1473 1347 1290 1423 1275 1408 1260 1405 1249 1389 1273
				1245 1380 1260 1420 1320 1452 1336 1467 1349 1275 1395 1264 1383 1252 1381 1243 1365 1252
				1210 1360 1250 1410 1301 1434 1310 1445 1320 1274 1401 1261 1386 1249 1381 1240 1369 1263
				1261 1409 1278 1452 1337 1479 1354 1497 1366 1279 1420 1272 1409 1259 1410 1252 1394 1256
				1206 1362 1247 1408 1297 1433 1309 1443 1320 1275 1399 1266 1386 1253 1381 1243 1372 1261
				1246 1365 1264 1407 1314 1431 1329 1444 1338 1267 1392 1261 1383 1252 1384 1245 1374 1245
				1145 1282 1182 1324 1224 1340 1236 1353 1246 1218 1333 1206 1320 1194 1314 1182 1303 1193
				1171 1285 1187 1324 1228 1342 1242 1354 1252 1209 1314 1200 1306 1191 1305 1185 1296 1182
				1150 1283 1187 1321 1224 1331 1236 1343 1246 1209 1309 1197 1293 1183 1288 1171 1276 1179
				1167 1303 1185 1344 1225 1359 1243 1375 1261 1236 1346 1222 1336 1212 1337 1203 1327 1192
				1158 1296 1198 1334 1229 1339 1241 1350 1255 1236 1330 1220 1317 1205 1315 1193 1303 1197
				1159 1278 1179 1317 1212 1326 1230 1341 1243 1216 1315 1205 1305 1194 1306 1187 1296 1173
				1157 1306 1199 1346 1225 1349 1239 1361 1250 1252 1352 1239 1339 1226 1338 1214 1322 1210
				1168 1288 1188 1327 1216 1334 1231 1346 1246 1236 1333 1225 1327 1215 1327 1210 1314 1189
				1152 1293 1194 1332 1216 1332 1228 1343 1240 1249 1350 1237 1338 1223 1333 1213 1317 1207
				1176 1317 1201 1359 1228 1365 1246 1383 1264 1257 1360 1245 1351 1234 1352 1228 1333 1201
				1060 1296 1192 1330 1211 1331 1223 1342 1236 1245 1342 1232 1329 1217 1327 1207 1305 1099
				1087 1302 1214 1342 1236 1362 1252 1359 1263 1240 1353 1234 1357 1224 1347 1216 1323 1108
				(-511) (-511) (-511)>;

			PS_Config_Lmt_FW_Rawdata_P = <
				1120 1114 1129 1113 1103 1121 1131 1141 1141 1129 1099 1099 1096 1099 1097 1100 1111 1099
				1107 1122 1121 1117 1114 1113 1108 1115 1148 1082 1156 1082 1087 1078 1079 1107 1085 1150
				1120 1111 1117 1110 1111 1111 1111 1120 1110 1138 1115 1111 1114 1114 1111 1117 1114 1134
				1106 1122 1108 1122 1121 1120 1127 1129 1143 1101 1101 1134 1124 1129 1122 1100 1120 1110
				1120 1114 1131 1110 1110 1121 1118 1114 1134 1131 1110 1118 1114 1110 1111 1121 1106 1121
				1115 1127 1122 1127 1125 1121 1120 1115 1115 1141 1129 1125 1121 1125 1121 1117 1134 1092
				1129 1107 1101 1104 1104 1134 1099 1142 1134 1142 1117 1108 1108 1115 1124 1118 1118 1121
				1115 1131 1117 1107 1120 1110 1131 1121 1113 1114 1134 1104 1113 1107 1114 1125 1108 1132
				1132 1115 1117 1114 1115 1117 1122 1141 1127 1120 1111 1122 1115 1118 1117 1128 1127 1110
				1118 1128 1132 1135 1122 1135 1127 1129 1141 1110 1104 1124 1132 1113 1124 1125 1107 1141
				1129 1115 1125 1131 1115 1134 1129 1108 1118 1134 1134 1118 1127 1117 1122 1117 1118 1138
				1141 1104 1113 1110 1115 1117 1121 1121 1141 1141 1085 1093 1101 1107 1106 1097 1124 1129
				1129 1101 1103 1113 1100 1124 1111 1114 1093 1128 1111 1121 1111 1127 1118 1131 1134 1117
				1111 1141 1134 1103 1129 1099 1094 1104 1124 1143 1153 1129 1121 1132 1131 1135 1107 1107
				1110 1104 1118 1110 1110 1103 1106 1138 1114 1114 1121 1124 1128 1101 1115 1103 1104 1127
				1120 1097 1101 1104 1096 1103 1101 1118 1159 1110 1103 1131 1129 1127 1135 1128 1124 1141
				1127 1115 1118 1122 1115 1129 1122 1100 1108 1124 1134 1111 1118 1115 1120 1108 1097 1132
				1117 1113 1101 1108 1115 1111 1114 1111 1120 1111 1146 1120 1122 1125 1127 1117 1117 1129
				1141 1118 1121 1114 1120 1107 1106 1103 1118 1129 1111 1129 1127 1124 1127 1132 1120 1110
				1141 1106 1111 1106 1104 1118 1108 1100 1103 1115 1121 1117 1117 1122 1120 1121 1120 1121
				1113 1122 1120 1108 1120 1107 1114 1108 1132 1139 1134 1139 1141 1142 1143 1138 1128 1115
				1142 1122 1118 1131 1122 1111 1145 1117 1139 1103 1117 1113 1120 1103 1113 1107 1115 1135
				1121 1127 1129 1120 1125 1107 1104 1128 1114 1114 1124 1131 1121 1125 1138 1134 1138 1127
				1117 1128 1127 1139 1132 1120 1124 1127 1124 1125 1138 1128 1131 1128 1121 1118 1120 1117
				1118 1128 1124 1127 1129 1127 1121 1120 1113 1132 1115 1117 1103 1108 1110 1107 1114 1100
				1127 1129 1125 1135 1125 1108 1128 1117 1115 1111 1111 1128 1089 1125 1129 1124 1131 1132
				1114 1111 1113 1110 1104 1129 1114 1104 1125 1142 1114 1106 1128 1117 1108 1110 1103 1118
				1111 1117 1117 1124 1121 1120 1117 1134 1134 1131 1134 1128 1122 1122 1120 1129 1132 1096
				1118 1108 1110 1110 1113 1117 1118 1114 1138 1131 1122 1106 1117 1106 1103 1108 1115 1108
				1117 1121 1115 1113 1118 1114 1110 1113 1143 1115 1127 1107 1092 1107 1099 1113 1114 1114
				1136 1097 1110 1107 1096 1108 1103 1106 1131 1106 1121 1121 1104 1120 1107 1127 1134 1128
				1131 1122 1125 1101 1127 1108 1114 1111 1100 1106 1111 1114 1086 1138 1093 1125 1125 1114
				1141 1120 1114 1110 1114 1113 1138 1110 1132 1128 1120 1124 1101 1132 1106 1127 1132 1114
				1131 1132 1138 1104 1124 1103 1125 1120 1110 1114 1117 1122 1120 1122 1106 1124 1125 1120
				1120 1124 1128 1103 1113 1107 1117 1136 1129 1141 1115 1110 1092 1114 1097 1115 1113 1118
				1125 1134 1128 1122 1125 1122 1141 1134 1122 1113 1131 1122 1125 1117 1118 1122 1129 1122
				2560 2560 2560>;

			PS_Config_Lmt_FW_Rawdata_N = <
				480 477 484 477 472 480 484 489 489 484 471 471 469 471 470 471 476 471
				474 481 480 478 477 477 475 478 492 463 495 463 466 462 462 474 465 493
				480 476 478 475 476 476 476 480 475 487 478 476 477 477 476 478 477 486
				474 481 475 481 480 480 483 484 490 472 472 486 481 484 481 471 480 475
				480 477 484 475 475 480 479 477 486 484 475 479 477 475 476 480 474 480
				478 483 481 483 482 480 480 478 478 489 484 482 480 482 480 478 486 468
				484 474 472 473 473 486 471 489 486 489 478 475 475 478 481 479 479 480
				478 484 478 474 480 475 484 480 477 477 486 473 477 474 477 482 475 485
				485 478 478 477 478 478 481 489 483 480 476 481 478 479 478 483 483 475
				479 483 485 486 481 486 483 484 489 475 473 481 485 477 481 482 474 489
				484 478 482 484 478 486 484 475 479 486 486 479 483 478 481 478 479 487
				489 473 477 475 478 478 480 480 489 489 465 468 472 474 474 470 481 484
				484 472 472 477 471 481 476 477 468 483 476 480 476 483 479 484 486 478
				476 489 486 472 484 471 469 473 481 490 494 484 480 485 484 486 474 474
				475 473 479 475 475 472 474 487 477 477 480 481 483 472 478 472 473 483
				480 470 472 473 469 472 472 479 496 475 472 484 484 483 486 483 481 489
				483 478 479 481 478 484 481 471 475 481 486 476 479 478 480 475 470 485
				478 477 472 475 478 476 477 476 480 476 491 480 481 482 483 478 478 484
				489 479 480 477 480 474 474 472 479 484 476 484 483 481 483 485 480 475
				489 474 476 474 473 479 475 471 472 478 480 478 478 481 480 480 480 480
				477 481 480 475 480 474 477 475 485 488 486 488 489 489 490 487 483 478
				489 481 479 484 481 476 490 478 488 472 478 477 480 472 477 474 478 486
				480 483 484 480 482 474 473 483 477 477 481 484 480 482 487 486 487 483
				478 483 483 488 485 480 481 483 481 482 487 483 484 483 480 479 480 478
				479 483 481 483 484 483 480 480 477 485 478 478 472 475 475 474 477 471
				483 484 482 486 482 475 483 478 478 476 476 483 466 482 484 481 484 485
				477 476 477 475 473 484 477 473 482 489 477 474 483 478 475 475 472 479
				476 478 478 481 480 480 478 486 486 484 486 483 481 481 480 484 485 469
				479 475 475 475 477 478 479 477 487 484 481 474 478 474 472 475 478 475
				478 480 478 477 479 477 475 477 490 478 483 474 468 474 471 477 477 477
				487 470 475 474 469 475 472 474 484 474 480 480 473 480 474 483 486 483
				484 481 482 472 483 475 477 476 471 474 476 477 465 487 468 482 482 477
				489 480 477 475 477 477 487 475 485 483 480 481 472 485 474 483 485 477
				484 485 487 473 481 472 482 480 475 477 478 481 480 481 474 481 482 480
				480 481 483 472 477 474 478 487 484 489 478 475 468 477 470 478 477 479
				482 486 483 481 482 481 489 486 481 477 484 481 482 478 479 481 484 481
				240 240 240>;

			PS_Config_Lmt_FW_CC_P = <
				42 42 42 42 44 42 42 44 45 45 42 42 42 42 42 42 42 42
				44 42 42 42 42 42 42 42 45 45 42 42 42 42 42 42 42 42
				44 42 42 42 42 42 42 44 45 45 42 42 42 42 42 42 42 44
				44 42 42 42 42 42 42 42 45 46 44 44 44 44 44 44 44 45
				44 42 42 42 42 42 42 44 45 44 42 42 42 42 42 42 42 44
				44 42 42 42 42 42 42 42 45 45 44 42 44 42 42 44 42 45
				42 42 42 42 42 42 42 42 45 44 42 42 42 42 42 42 42 44
				44 42 42 42 42 42 42 42 45 45 44 42 42 42 42 44 42 44
				44 42 42 42 42 42 42 44 45 45 44 44 44 44 44 44 44 44
				44 42 44 44 44 44 44 44 45 45 44 42 42 42 42 42 42 44
				42 42 42 42 42 42 44 44 45 45 44 44 44 42 44 44 44 44
				42 42 42 42 42 42 42 42 45 45 45 44 44 42 42 44 42 44
				42 42 42 42 42 42 42 44 45 45 44 44 44 42 44 42 42 44
				44 42 42 44 42 44 44 44 45 45 44 42 42 42 42 42 42 44
				42 42 42 42 42 42 42 44 45 45 44 42 42 42 42 42 42 44
				44 42 44 44 42 44 44 44 45 46 45 44 44 42 44 42 42 44
				42 42 42 42 42 42 42 44 45 45 44 42 44 44 44 42 42 44
				44 42 42 42 42 42 42 44 46 46 44 42 42 42 42 42 42 44
				44 42 42 42 42 42 42 42 44 42 42 42 44 42 42 42 42 44
				44 42 42 42 42 44 44 42 44 45 42 44 44 42 42 42 42 44
				44 42 42 42 42 42 42 42 44 44 42 44 42 42 42 42 42 44
				44 44 44 44 44 44 44 44 44 45 42 44 44 42 42 42 42 44
				44 42 42 42 42 44 44 42 44 42 42 42 42 42 42 42 42 44
				44 44 44 44 44 44 44 44 44 44 42 42 42 42 42 42 42 44
				42 42 42 42 42 41 42 42 45 44 42 42 42 42 42 42 42 44
				44 42 42 42 42 42 42 42 45 45 42 42 42 42 42 42 42 44
				42 42 42 42 42 41 42 42 45 44 42 42 42 42 42 42 42 44
				44 42 42 42 42 42 42 42 44 45 44 44 42 42 42 44 44 44
				44 42 42 42 42 42 42 42 45 44 42 42 42 42 42 42 42 44
				44 42 42 42 42 42 42 42 44 45 42 42 42 42 42 42 42 44
				42 42 42 42 42 42 42 42 44 44 42 42 42 42 42 42 42 44
				44 42 42 42 42 42 42 42 44 45 42 42 42 42 42 42 42 44
				42 42 42 42 42 42 42 42 44 44 42 42 42 42 42 42 42 44
				44 42 42 42 42 42 42 42 44 45 42 42 42 42 42 42 42 44
				42 42 42 41 42 41 42 42 44 44 42 42 42 42 42 42 42 42
				44 44 44 44 44 44 44 44 45 45 44 42 42 44 42 42 42 44
				314 314 314>;

			PS_Config_Lmt_FW_CC_N = <
				19 19 19 19 19 19 19 19 20 20 19 19 19 19 19 19 19 19
				19 19 19 19 19 19 19 19 20 20 19 19 19 19 19 19 19 19
				19 19 19 19 19 19 19 19 20 20 19 19 19 19 19 19 19 19
				19 19 19 19 19 19 19 19 20 21 19 19 19 19 19 19 19 20
				19 19 19 19 19 19 19 19 20 19 19 19 19 19 19 19 19 19
				19 19 19 19 19 19 19 19 20 20 19 19 19 19 19 19 19 20
				19 19 19 19 19 19 19 19 20 19 19 19 19 19 19 19 19 19
				19 19 19 19 19 19 19 19 20 20 19 19 19 19 19 19 19 19
				19 19 19 19 19 19 19 19 20 20 19 19 19 19 19 19 19 19
				19 19 19 19 19 19 19 19 20 20 19 19 19 19 19 19 19 19
				19 19 19 19 19 19 19 19 20 20 19 19 19 19 19 19 19 19
				19 19 19 19 19 19 19 19 20 20 20 19 19 19 19 19 19 19
				19 19 19 19 19 19 19 19 20 20 19 19 19 19 19 19 19 19
				19 19 19 19 19 19 19 19 20 20 19 19 19 19 19 19 19 19
				19 19 19 19 19 19 19 19 20 20 19 19 19 19 19 19 19 19
				19 19 19 19 19 19 19 19 20 21 20 19 19 19 19 19 19 19
				19 19 19 19 19 19 19 19 20 20 19 19 19 19 19 19 19 19
				19 19 19 19 19 19 19 19 21 21 19 19 19 19 19 19 19 19
				19 19 19 19 19 19 19 19 19 19 19 19 19 19 19 19 19 19
				19 19 19 19 19 19 19 19 19 20 19 19 19 19 19 19 19 19
				19 19 19 19 19 19 19 19 19 19 19 19 19 19 19 19 19 19
				19 19 19 19 19 19 19 19 19 20 19 19 19 19 19 19 19 19
				19 19 19 19 19 19 19 19 19 19 19 19 19 19 19 19 19 19
				19 19 19 19 19 19 19 19 19 19 19 19 19 19 19 19 19 19
				19 19 19 19 19 18 19 19 20 19 19 19 19 19 19 19 19 19
				19 19 19 19 19 19 19 19 20 20 19 19 19 19 19 19 19 19
				19 19 19 19 19 18 19 19 20 19 19 19 19 19 19 19 19 19
				19 19 19 19 19 19 19 19 19 20 19 19 19 19 19 19 19 19
				19 19 19 19 19 19 19 19 20 19 19 19 19 19 19 19 19 19
				19 19 19 19 19 19 19 19 19 20 19 19 19 19 19 19 19 19
				19 19 19 19 19 19 19 19 19 19 19 19 19 19 19 19 19 19
				19 19 19 19 19 19 19 19 19 20 19 19 19 19 19 19 19 19
				19 19 19 19 19 19 19 19 19 19 19 19 19 19 19 19 19 19
				19 19 19 19 19 19 19 19 19 20 19 19 19 19 19 19 19 19
				19 19 19 18 19 18 19 19 19 19 19 19 19 19 19 19 19 19
				19 19 19 19 19 19 19 19 20 20 19 19 19 19 19 19 19 19
				0 0 0>;

			PS_Config_Lmt_FW_Diff_P = <
				50 50 50 50 50 50 50 50 50 50 50 50 50 50 50 50 50 50
				50 50 50 50 50 50 50 50 50 50 50 50 50 50 50 50 50 50
				50 50 50 50 50 50 50 50 50 50 50 50 50 50 50 50 50 50
				50 50 50 50 50 50 50 50 50 50 50 50 50 50 50 50 50 50
				50 50 50 50 50 50 50 50 50 50 50 50 50 50 50 50 50 50
				50 50 50 50 50 50 50 50 50 50 50 50 50 50 50 50 50 50
				50 50 50 50 50 50 50 50 50 50 50 50 50 50 50 50 50 50
				50 50 50 50 50 50 50 50 50 50 50 50 50 50 50 50 50 50
				50 50 50 50 50 50 50 50 50 50 50 50 50 50 50 50 50 50
				50 50 50 50 50 50 50 50 50 50 50 50 50 50 50 50 50 50
				50 50 50 50 50 50 50 50 50 50 50 50 50 50 50 50 50 50
				50 50 50 50 50 50 50 50 50 50 50 50 50 50 50 50 50 50
				50 50 50 50 50 50 50 50 50 50 50 50 50 50 50 50 50 50
				50 50 50 50 50 50 50 50 50 50 50 50 50 50 50 50 50 50
				50 50 50 50 50 50 50 50 50 50 50 50 50 50 50 50 50 50
				50 50 50 50 50 50 50 50 50 50 50 50 50 50 50 50 50 50
				50 50 50 50 50 50 50 50 50 50 50 50 50 50 50 50 50 50
				50 50 50 50 50 50 50 50 50 50 50 50 50 50 50 50 50 50
				50 50 50 50 50 50 50 50 50 50 50 50 50 50 50 50 50 50
				50 50 50 50 50 50 50 50 50 50 50 50 50 50 50 50 50 50
				50 50 50 50 50 50 50 50 50 50 50 50 50 50 50 50 50 50
				50 50 50 50 50 50 50 50 50 50 50 50 50 50 50 50 50 50
				50 50 50 50 50 50 50 50 50 50 50 50 50 50 50 50 50 50
				50 50 50 50 50 50 50 50 50 50 50 50 50 50 50 50 50 50
				50 50 50 50 50 50 50 50 50 50 50 50 50 50 50 50 50 50
				50 50 50 50 50 50 50 50 50 50 50 50 50 50 50 50 50 50
				50 50 50 50 50 50 50 50 50 50 50 50 50 50 50 50 50 50
				50 50 50 50 50 50 50 50 50 50 50 50 50 50 50 50 50 50
				50 50 50 50 50 50 50 50 50 50 50 50 50 50 50 50 50 50
				50 50 50 50 50 50 50 50 50 50 50 50 50 50 50 50 50 50
				50 50 50 50 50 50 50 50 50 50 50 50 50 50 50 50 50 50
				50 50 50 50 50 50 50 50 50 50 50 50 50 50 50 50 50 50
				50 50 50 50 50 50 50 50 50 50 50 50 50 50 50 50 50 50
				50 50 50 50 50 50 50 50 50 50 50 50 50 50 50 50 50 50
				50 50 50 50 50 50 50 50 50 50 50 50 50 50 50 50 50 50
				50 50 50 50 50 50 50 50 50 50 50 50 50 50 50 50 50 50
				75 75 75>;

			PS_Config_Lmt_FW_Diff_N = <
				(-50) (-50) (-50) (-50) (-50) (-50) (-50) (-50) (-50) (-50) (-50) (-50) (-50) (-50) (-50) (-50) (-50) (-50)
				(-50) (-50) (-50) (-50) (-50) (-50) (-50) (-50) (-50) (-50) (-50) (-50) (-50) (-50) (-50) (-50) (-50) (-50)
				(-50) (-50) (-50) (-50) (-50) (-50) (-50) (-50) (-50) (-50) (-50) (-50) (-50) (-50) (-50) (-50) (-50) (-50)
				(-50) (-50) (-50) (-50) (-50) (-50) (-50) (-50) (-50) (-50) (-50) (-50) (-50) (-50) (-50) (-50) (-50) (-50)
				(-50) (-50) (-50) (-50) (-50) (-50) (-50) (-50) (-50) (-50) (-50) (-50) (-50) (-50) (-50) (-50) (-50) (-50)
				(-50) (-50) (-50) (-50) (-50) (-50) (-50) (-50) (-50) (-50) (-50) (-50) (-50) (-50) (-50) (-50) (-50) (-50)
				(-50) (-50) (-50) (-50) (-50) (-50) (-50) (-50) (-50) (-50) (-50) (-50) (-50) (-50) (-50) (-50) (-50) (-50)
				(-50) (-50) (-50) (-50) (-50) (-50) (-50) (-50) (-50) (-50) (-50) (-50) (-50) (-50) (-50) (-50) (-50) (-50)
				(-50) (-50) (-50) (-50) (-50) (-50) (-50) (-50) (-50) (-50) (-50) (-50) (-50) (-50) (-50) (-50) (-50) (-50)
				(-50) (-50) (-50) (-50) (-50) (-50) (-50) (-50) (-50) (-50) (-50) (-50) (-50) (-50) (-50) (-50) (-50) (-50)
				(-50) (-50) (-50) (-50) (-50) (-50) (-50) (-50) (-50) (-50) (-50) (-50) (-50) (-50) (-50) (-50) (-50) (-50)
				(-50) (-50) (-50) (-50) (-50) (-50) (-50) (-50) (-50) (-50) (-50) (-50) (-50) (-50) (-50) (-50) (-50) (-50)
				(-50) (-50) (-50) (-50) (-50) (-50) (-50) (-50) (-50) (-50) (-50) (-50) (-50) (-50) (-50) (-50) (-50) (-50)
				(-50) (-50) (-50) (-50) (-50) (-50) (-50) (-50) (-50) (-50) (-50) (-50) (-50) (-50) (-50) (-50) (-50) (-50)
				(-50) (-50) (-50) (-50) (-50) (-50) (-50) (-50) (-50) (-50) (-50) (-50) (-50) (-50) (-50) (-50) (-50) (-50)
				(-50) (-50) (-50) (-50) (-50) (-50) (-50) (-50) (-50) (-50) (-50) (-50) (-50) (-50) (-50) (-50) (-50) (-50)
				(-50) (-50) (-50) (-50) (-50) (-50) (-50) (-50) (-50) (-50) (-50) (-50) (-50) (-50) (-50) (-50) (-50) (-50)
				(-50) (-50) (-50) (-50) (-50) (-50) (-50) (-50) (-50) (-50) (-50) (-50) (-50) (-50) (-50) (-50) (-50) (-50)
				(-50) (-50) (-50) (-50) (-50) (-50) (-50) (-50) (-50) (-50) (-50) (-50) (-50) (-50) (-50) (-50) (-50) (-50)
				(-50) (-50) (-50) (-50) (-50) (-50) (-50) (-50) (-50) (-50) (-50) (-50) (-50) (-50) (-50) (-50) (-50) (-50)
				(-50) (-50) (-50) (-50) (-50) (-50) (-50) (-50) (-50) (-50) (-50) (-50) (-50) (-50) (-50) (-50) (-50) (-50)
				(-50) (-50) (-50) (-50) (-50) (-50) (-50) (-50) (-50) (-50) (-50) (-50) (-50) (-50) (-50) (-50) (-50) (-50)
				(-50) (-50) (-50) (-50) (-50) (-50) (-50) (-50) (-50) (-50) (-50) (-50) (-50) (-50) (-50) (-50) (-50) (-50)
				(-50) (-50) (-50) (-50) (-50) (-50) (-50) (-50) (-50) (-50) (-50) (-50) (-50) (-50) (-50) (-50) (-50) (-50)
				(-50) (-50) (-50) (-50) (-50) (-50) (-50) (-50) (-50) (-50) (-50) (-50) (-50) (-50) (-50) (-50) (-50) (-50)
				(-50) (-50) (-50) (-50) (-50) (-50) (-50) (-50) (-50) (-50) (-50) (-50) (-50) (-50) (-50) (-50) (-50) (-50)
				(-50) (-50) (-50) (-50) (-50) (-50) (-50) (-50) (-50) (-50) (-50) (-50) (-50) (-50) (-50) (-50) (-50) (-50)
				(-50) (-50) (-50) (-50) (-50) (-50) (-50) (-50) (-50) (-50) (-50) (-50) (-50) (-50) (-50) (-50) (-50) (-50)
				(-50) (-50) (-50) (-50) (-50) (-50) (-50) (-50) (-50) (-50) (-50) (-50) (-50) (-50) (-50) (-50) (-50) (-50)
				(-50) (-50) (-50) (-50) (-50) (-50) (-50) (-50) (-50) (-50) (-50) (-50) (-50) (-50) (-50) (-50) (-50) (-50)
				(-50) (-50) (-50) (-50) (-50) (-50) (-50) (-50) (-50) (-50) (-50) (-50) (-50) (-50) (-50) (-50) (-50) (-50)
				(-50) (-50) (-50) (-50) (-50) (-50) (-50) (-50) (-50) (-50) (-50) (-50) (-50) (-50) (-50) (-50) (-50) (-50)
				(-50) (-50) (-50) (-50) (-50) (-50) (-50) (-50) (-50) (-50) (-50) (-50) (-50) (-50) (-50) (-50) (-50) (-50)
				(-50) (-50) (-50) (-50) (-50) (-50) (-50) (-50) (-50) (-50) (-50) (-50) (-50) (-50) (-50) (-50) (-50) (-50)
				(-50) (-50) (-50) (-50) (-50) (-50) (-50) (-50) (-50) (-50) (-50) (-50) (-50) (-50) (-50) (-50) (-50) (-50)
				(-50) (-50) (-50) (-50) (-50) (-50) (-50) (-50) (-50) (-50) (-50) (-50) (-50) (-50) (-50) (-50) (-50) (-50)
				(-75) (-75) (-75)>;

			PS_Config_Diff_Test_Frame = <50>;
		};
	};
};
